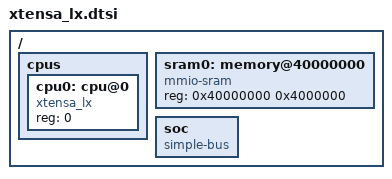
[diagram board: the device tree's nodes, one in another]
/*
 * Copyright (c) 2024 Cadence Design Systems, Inc.
 *
 * SPDX-License-Identifier: Apache-2.0
 */

#include "skeleton.dtsi"

/ {
	cpus {
		#address-cells = <1>;
		#size-cells = <0>;

		cpu0: cpu@0 {
			device_type = "cpu";
			compatible = "xtensa_lx";
			reg = <0>;
		};
	};

	sram0: memory@40000000 {
		device_type = "memory";
		compatible = "mmio-sram";
		reg = <0x40000000 0x4000000>;
	};

	soc {
		#address-cells = <1>;
		#size-cells = <1>;
		compatible = "simple-bus";
		ranges;

	};
};
